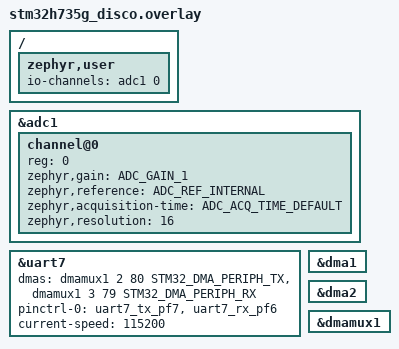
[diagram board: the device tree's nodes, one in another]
/*
 * SPDX-License-Identifier: Apache-2.0
 *
 * Copyright (c) Benjamin Björnsson <benjamin.bjornsson@gmail.com>
 */

/ {
	zephyr,user {
		/* adjust channel number according to pinmux in board.dts */
		io-channels = <&adc1 0>;
	};
};

&adc1 {
	#address-cells = <1>;
	#size-cells = <0>;

	channel@0 {
		reg = <0>;
		zephyr,gain = "ADC_GAIN_1";
		zephyr,reference = "ADC_REF_INTERNAL";
		zephyr,acquisition-time = <ADC_ACQ_TIME_DEFAULT>;
		zephyr,resolution = <16>;
	};
};

dut: &uart7 {
	dmas = <&dmamux1 2 80 STM32_DMA_PERIPH_TX>,
	       <&dmamux1 3 79 STM32_DMA_PERIPH_RX>;
	dma-names = "tx", "rx";
	pinctrl-0 = <&uart7_tx_pf7 &uart7_rx_pf6>;
	pinctrl-names = "default";
	current-speed = <115200>;
	status = "okay";
};

&dma1 {
	status = "okay";
};

&dma2 {
	status = "okay";
};

&dmamux1 {
	status = "okay";
};
